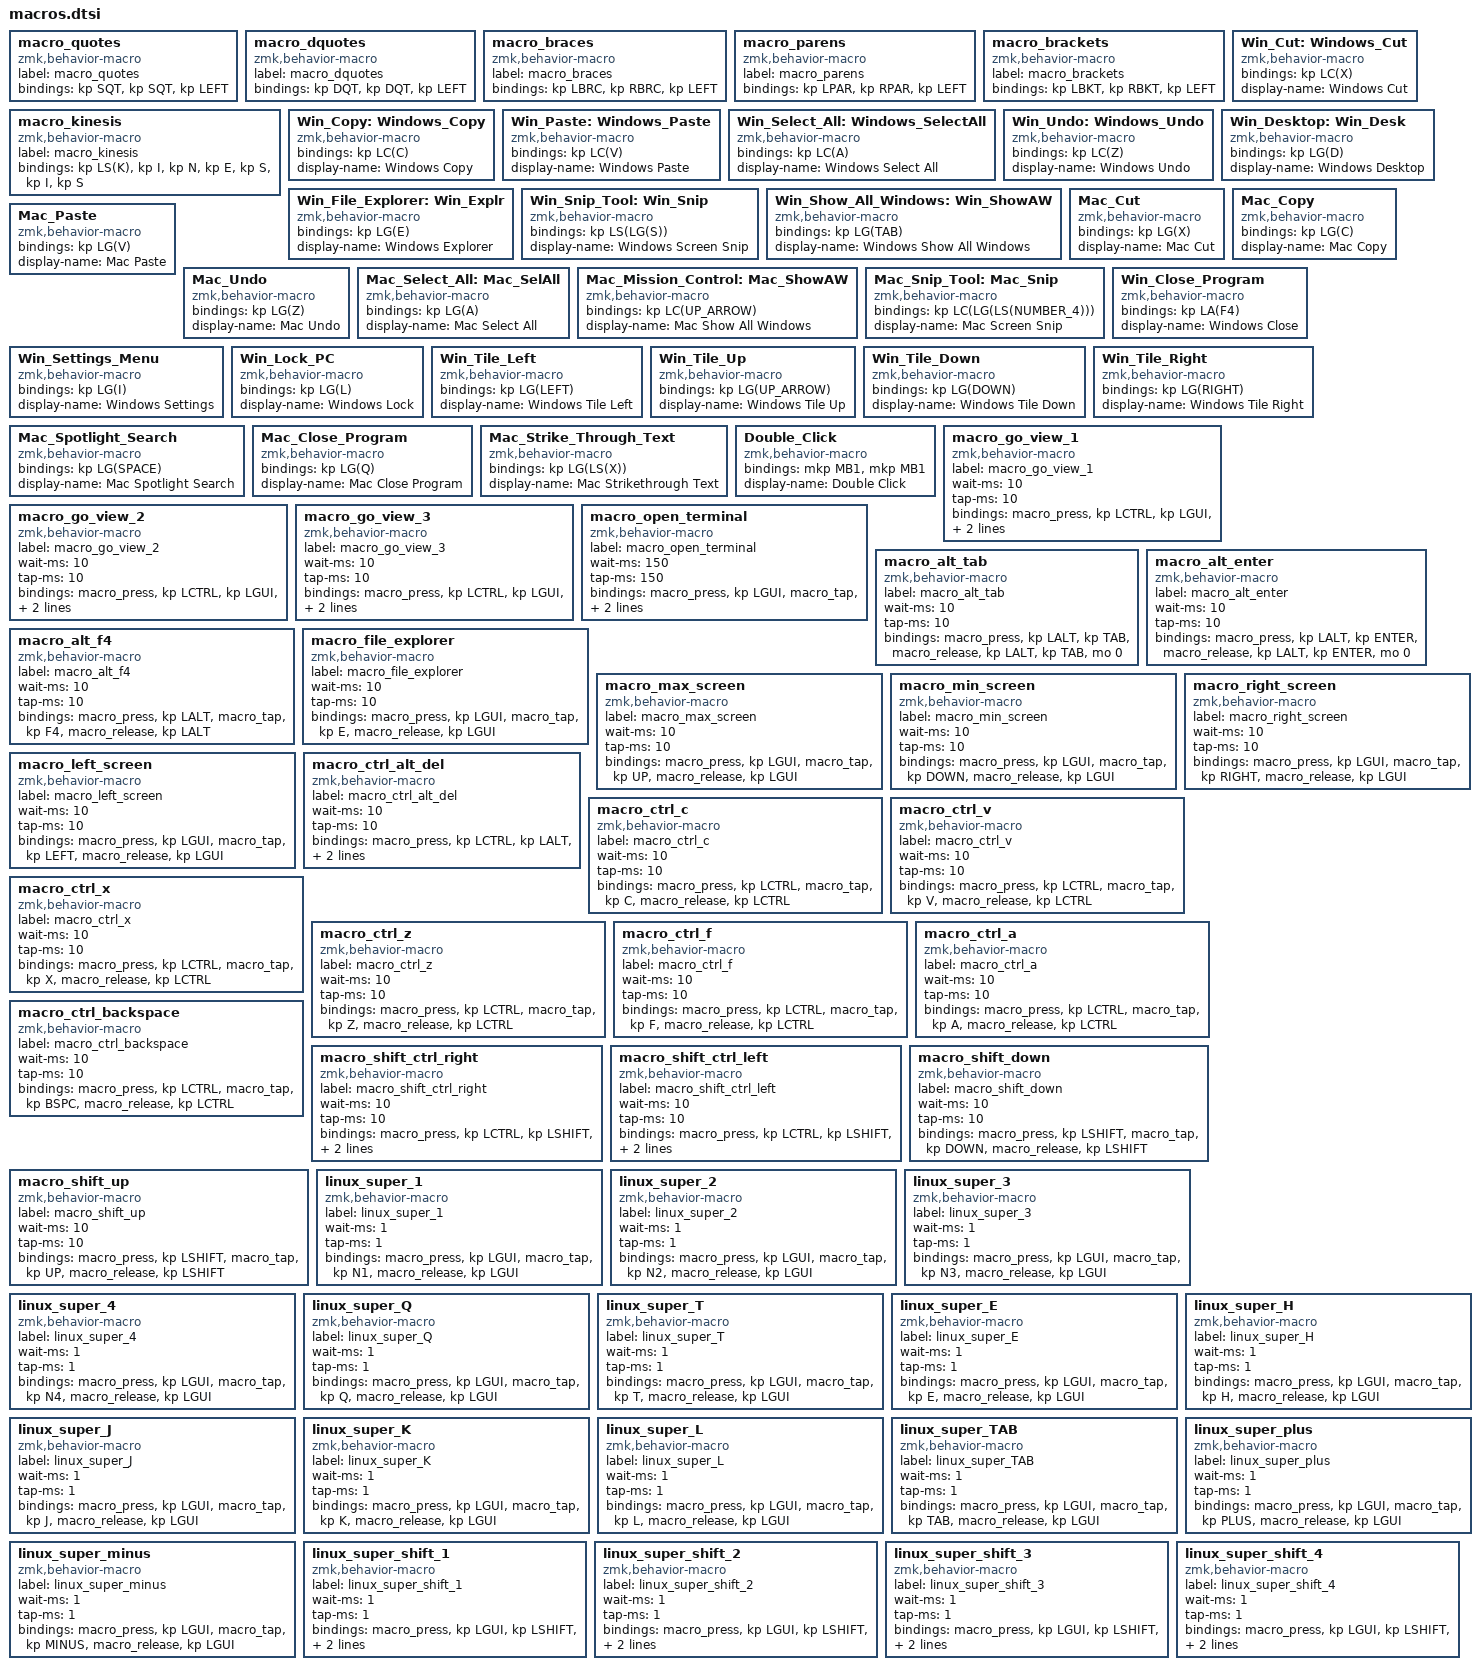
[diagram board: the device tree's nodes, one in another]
macro_quotes: macro_quotes {
    compatible = "zmk,behavior-macro";
    label = "macro_quotes";
    #binding-cells = <0>;
    bindings = <&kp SQT>, <&kp SQT>, <&kp LEFT>;
};
macro_dquotes: macro_dquotes {
    compatible = "zmk,behavior-macro";
    label = "macro_dquotes";
    #binding-cells = <0>;
    bindings = <&kp DQT>, <&kp DQT>, <&kp LEFT>;
};
macro_braces: macro_braces {
    compatible = "zmk,behavior-macro";
    label = "macro_braces";
    #binding-cells = <0>;
    bindings = <&kp LBRC>, <&kp RBRC>, <&kp LEFT>;
};
macro_parens: macro_parens {
    compatible = "zmk,behavior-macro";
    label = "macro_parens";
    #binding-cells = <0>;
    bindings = <&kp LPAR>, <&kp RPAR>, <&kp LEFT>;
};
macro_brackets: macro_brackets {
    compatible = "zmk,behavior-macro";
    label = "macro_brackets";
    #binding-cells = <0>;
    bindings = <&kp LBKT>, <&kp RBKT>, <&kp LEFT>;
};
macro_kinesis: macro_kinesis {
    compatible = "zmk,behavior-macro";
    label = "macro_kinesis";
    #binding-cells = <0>;
    bindings = <&kp LS(K)>, <&kp I>, <&kp N>, <&kp E>, <&kp S>, <&kp I>, <&kp S>;
};
Win_Cut: Windows_Cut {
    compatible = "zmk,behavior-macro";
    #binding-cells = <0>;
    bindings = <&kp LC(X)>;
    display-name = "Windows Cut";
};

Win_Copy: Windows_Copy {
    compatible = "zmk,behavior-macro";
    #binding-cells = <0>;
    bindings = <&kp LC(C)>;
    display-name = "Windows Copy";
};

Win_Paste: Windows_Paste {
    compatible = "zmk,behavior-macro";
    #binding-cells = <0>;
    bindings = <&kp LC(V)>;
    display-name = "Windows Paste";
};

Win_Select_All: Windows_SelectAll {
    compatible = "zmk,behavior-macro";
    #binding-cells = <0>;
    bindings = <&kp LC(A)>;
    display-name = "Windows Select All";
};

Win_Undo: Windows_Undo {
    compatible = "zmk,behavior-macro";
    #binding-cells = <0>;
    bindings = <&kp LC(Z)>;
    display-name = "Windows Undo";
};

Win_Desktop: Win_Desk {
    compatible = "zmk,behavior-macro";
    #binding-cells = <0>;
    bindings = <&kp LG(D)>;
    display-name = "Windows Desktop";
};

Win_File_Explorer: Win_Explr {
    compatible = "zmk,behavior-macro";
    #binding-cells = <0>;
    bindings = <&kp LG(E)>;
    display-name = "Windows Explorer";
};

Win_Snip_Tool: Win_Snip {
    compatible = "zmk,behavior-macro";
    #binding-cells = <0>;
    bindings = <&kp LS(LG(S))>;
    display-name = "Windows Screen Snip";
};

Win_Show_All_Windows: Win_ShowAW {
    compatible = "zmk,behavior-macro";
    #binding-cells = <0>;
    bindings = <&kp LG(TAB)>;
    display-name = "Windows Show All Windows";
};

Mac_Cut: Mac_Cut {
    compatible = "zmk,behavior-macro";
    #binding-cells = <0>;
    bindings = <&kp LG(X)>;
    display-name = "Mac Cut";
};

Mac_Copy: Mac_Copy {
    compatible = "zmk,behavior-macro";
    #binding-cells = <0>;
    bindings = <&kp LG(C)>;
    display-name = "Mac Copy";
};

Mac_Paste: Mac_Paste {
    compatible = "zmk,behavior-macro";
    #binding-cells = <0>;
    bindings = <&kp LG(V)>;
    display-name = "Mac Paste";
};

Mac_Undo: Mac_Undo {
    compatible = "zmk,behavior-macro";
    #binding-cells = <0>;
    bindings = <&kp LG(Z)>;
    display-name = "Mac Undo";
};

Mac_Select_All: Mac_SelAll {
    compatible = "zmk,behavior-macro";
    #binding-cells = <0>;
    bindings = <&kp LG(A)>;
    display-name = "Mac Select All";
};

Mac_Mission_Control: Mac_ShowAW {
    compatible = "zmk,behavior-macro";
    #binding-cells = <0>;
    bindings = <&kp LC(UP_ARROW)>;
    display-name = "Mac Show All Windows";
};

Mac_Snip_Tool: Mac_Snip {
    compatible = "zmk,behavior-macro";
    #binding-cells = <0>;
    bindings = <&kp LC(LG(LS(NUMBER_4)))>;
    display-name = "Mac Screen Snip";
};

Win_Close_Program: Win_Close_Program {
    compatible = "zmk,behavior-macro";
    #binding-cells = <0>;
    bindings = <&kp LA(F4)>;
    display-name = "Windows Close";
};

Win_Settings_Menu: Win_Settings_Menu {
    compatible = "zmk,behavior-macro";
    #binding-cells = <0>;
    bindings = <&kp LG(I)>;
    display-name = "Windows Settings";
};

Win_Lock_PC: Win_Lock_PC {
    compatible = "zmk,behavior-macro";
    #binding-cells = <0>;
    bindings = <&kp LG(L)>;
    display-name = "Windows Lock";
};

Win_Tile_Left: Win_Tile_Left {
    compatible = "zmk,behavior-macro";
    #binding-cells = <0>;
    bindings = <&kp LG(LEFT)>;
    display-name = "Windows Tile Left";
};

Win_Tile_Up: Win_Tile_Up {
    compatible = "zmk,behavior-macro";
    #binding-cells = <0>;
    bindings = <&kp LG(UP_ARROW)>;
    display-name = "Windows Tile Up";
};

Win_Tile_Down: Win_Tile_Down {
    compatible = "zmk,behavior-macro";
    #binding-cells = <0>;
    bindings = <&kp LG(DOWN)>;
    display-name = "Windows Tile Down";
};

Win_Tile_Right: Win_Tile_Right {
    compatible = "zmk,behavior-macro";
    #binding-cells = <0>;
    bindings = <&kp LG(RIGHT)>;
    display-name = "Windows Tile Right";
};

Mac_Spotlight_Search: Mac_Spotlight_Search {
    compatible = "zmk,behavior-macro";
    #binding-cells = <0>;
    bindings = <&kp LG(SPACE)>;
    display-name = "Mac Spotlight Search";
};

Mac_Close_Program: Mac_Close_Program {
    compatible = "zmk,behavior-macro";
    #binding-cells = <0>;
    bindings = <&kp LG(Q)>;
    display-name = "Mac Close Program";
};

Mac_Strike_Through_Text: Mac_Strike_Through_Text {
    compatible = "zmk,behavior-macro";
    #binding-cells = <0>;
    bindings = <&kp LG(LS(X))>;
    display-name = "Mac Strikethrough Text";
};

Double_Click: Double_Click {
    compatible = "zmk,behavior-macro";
    #binding-cells = <0>;
    bindings = <&mkp MB1 &mkp MB1>;
    display-name = "Double Click";
};

macro_go_view_1: macro_go_view_1 {
    label = "macro_go_view_1";
    compatible = "zmk,behavior-macro";
    #binding-cells = <0>;
    wait-ms = <10>;
    tap-ms = <10>;
    bindings 
    = <&macro_press &kp LCTRL &kp LGUI>
    , <&macro_tap &kp LEFT &kp LEFT>
    , <&macro_release &kp LCTRL &kp LGUI>;
};
macro_go_view_2: macro_go_view_2 {
    label = "macro_go_view_2";
    compatible = "zmk,behavior-macro";
    #binding-cells = <0>;
    wait-ms = <10>;
    tap-ms = <10>;
    bindings 
    = <&macro_press &kp LCTRL &kp LGUI>
    , <&macro_tap &kp LEFT &kp LEFT &kp RIGHT>
    , <&macro_release &kp LCTRL &kp LGUI>;
};
macro_go_view_3: macro_go_view_3 {
    label = "macro_go_view_3";
    compatible = "zmk,behavior-macro";
    #binding-cells = <0>;
    wait-ms = <10>;
    tap-ms = <10>;
    bindings 
    = <&macro_press &kp LCTRL &kp LGUI>
    , <&macro_tap &kp LEFT &kp LEFT &kp RIGHT &kp RIGHT>
    , <&macro_release &kp LCTRL &kp LGUI>;
};
macro_open_terminal: macro_open_terminal {
    label = "macro_open_terminal";
    compatible = "zmk,behavior-macro";
    #binding-cells = <0>;
    wait-ms = <150>;
    tap-ms = <150>;
    bindings 
    = <&macro_press &kp LGUI>
    , <&macro_tap &kp X>
    , <&macro_release &kp LGUI>
    , <&macro_tap &kp I>;
};
macro_alt_tab: macro_alt_tab {
    label = "macro_alt_tab";
    compatible = "zmk,behavior-macro";
    #binding-cells = <0>;
    wait-ms = <10>;
    tap-ms = <10>;
    bindings 
    = <&macro_press &kp LALT &kp TAB>
    , <&macro_release &kp LALT &kp TAB &mo 0>;
};
macro_alt_enter: macro_alt_enter {
    label = "macro_alt_enter";
    compatible = "zmk,behavior-macro";
    #binding-cells = <0>;
    wait-ms = <10>;
    tap-ms = <10>;
    bindings 
    = <&macro_press &kp LALT &kp ENTER>
    , <&macro_release &kp LALT &kp ENTER &mo 0>;
};
macro_alt_f4: macro_alt_f4 {
    label = "macro_alt_f4";
    compatible = "zmk,behavior-macro";
    #binding-cells = <0>;
    wait-ms = <10>;
    tap-ms = <10>;
    bindings 
    = <&macro_press &kp LALT>
    , <&macro_tap &kp F4>
    , <&macro_release &kp LALT>;
};
macro_file_explorer: macro_file_explorer {
    label = "macro_file_explorer";
    compatible = "zmk,behavior-macro";
    #binding-cells = <0>;
    wait-ms = <10>;
    tap-ms = <10>;
    bindings 
    = <&macro_press &kp LGUI>
    , <&macro_tap &kp E>
    , <&macro_release &kp LGUI>;
};
macro_max_screen: macro_max_screen {
    label = "macro_max_screen";
    compatible = "zmk,behavior-macro";
    #binding-cells = <0>;
    wait-ms = <10>;
    tap-ms = <10>;
    bindings 
    = <&macro_press &kp LGUI>
    , <&macro_tap &kp UP>
    , <&macro_release &kp LGUI>;
};
macro_min_screen: macro_min_screen {
    label = "macro_min_screen";
    compatible = "zmk,behavior-macro";
    #binding-cells = <0>;
    wait-ms = <10>;
    tap-ms = <10>;
    bindings 
    = <&macro_press &kp LGUI>
    , <&macro_tap &kp DOWN>
    , <&macro_release &kp LGUI>;
};
macro_right_screen: macro_right_screen {
    label = "macro_right_screen";
    compatible = "zmk,behavior-macro";
    #binding-cells = <0>;
    wait-ms = <10>;
    tap-ms = <10>;
    bindings 
    = <&macro_press &kp LGUI>
    , <&macro_tap &kp RIGHT>
    , <&macro_release &kp LGUI>;
};
macro_left_screen: macro_left_screen {
    label = "macro_left_screen";
    compatible = "zmk,behavior-macro";
    #binding-cells = <0>;
    wait-ms = <10>;
    tap-ms = <10>;
    bindings 
    = <&macro_press &kp LGUI>
    , <&macro_tap &kp LEFT>
    , <&macro_release &kp LGUI>;
};
macro_ctrl_alt_del: macro_ctrl_alt_del {
    label = "macro_ctrl_alt_del";
    compatible = "zmk,behavior-macro";
    #binding-cells = <0>;
    wait-ms = <10>;
    tap-ms = <10>;
    bindings 
    = <&macro_press &kp LCTRL &kp LALT>
    , <&macro_tap &kp DEL>
    , <&macro_release &kp LCTRL &kp LALT>;
};
macro_ctrl_c: macro_ctrl_c {
    label = "macro_ctrl_c";
    compatible = "zmk,behavior-macro";
    #binding-cells = <0>;
    wait-ms = <10>;
    tap-ms = <10>;
    bindings 
    = <&macro_press &kp LCTRL>
    , <&macro_tap &kp C>
    , <&macro_release &kp LCTRL>;
};
macro_ctrl_v: macro_ctrl_v {
    label = "macro_ctrl_v";
    compatible = "zmk,behavior-macro";
    #binding-cells = <0>;
    wait-ms = <10>;
    tap-ms = <10>;
    bindings 
    = <&macro_press &kp LCTRL>
    , <&macro_tap &kp V>
    , <&macro_release &kp LCTRL>;
};
macro_ctrl_x: macro_ctrl_x {
    label = "macro_ctrl_x";
    compatible = "zmk,behavior-macro";
    #binding-cells = <0>;
    wait-ms = <10>;
    tap-ms = <10>;
    bindings 
    = <&macro_press &kp LCTRL>
    , <&macro_tap &kp X>
    , <&macro_release &kp LCTRL>;
};
macro_ctrl_z: macro_ctrl_z {
    label = "macro_ctrl_z";
    compatible = "zmk,behavior-macro";
    #binding-cells = <0>;
    wait-ms = <10>;
    tap-ms = <10>;
    bindings 
    = <&macro_press &kp LCTRL>
    , <&macro_tap &kp Z>
    , <&macro_release &kp LCTRL>;
};
macro_ctrl_f: macro_ctrl_f {
    label = "macro_ctrl_f";
    compatible = "zmk,behavior-macro";
    #binding-cells = <0>;
    wait-ms = <10>;
    tap-ms = <10>;
    bindings 
    = <&macro_press &kp LCTRL>
    , <&macro_tap &kp F>
    , <&macro_release &kp LCTRL>;
};
macro_ctrl_a: macro_ctrl_a {
    label = "macro_ctrl_a";
    compatible = "zmk,behavior-macro";
    #binding-cells = <0>;
    wait-ms = <10>;
    tap-ms = <10>;
    bindings 
    = <&macro_press &kp LCTRL>
    , <&macro_tap &kp A>
    , <&macro_release &kp LCTRL>;
};
macro_ctrl_backspace: macro_ctrl_backspace {
    label = "macro_ctrl_backspace";
    compatible = "zmk,behavior-macro";
    #binding-cells = <0>;
    wait-ms = <10>;
    tap-ms = <10>;
    bindings 
    = <&macro_press &kp LCTRL>
    , <&macro_tap &kp BSPC>
    , <&macro_release &kp LCTRL>;
};
macro_shift_ctrl_right: macro_shift_ctrl_right {
    label = "macro_shift_ctrl_right";
    compatible = "zmk,behavior-macro";
    #binding-cells = <0>;
    wait-ms = <10>;
    tap-ms = <10>;
    bindings 
    = <&macro_press &kp LCTRL &kp LSHIFT>
    , <&macro_tap &kp RIGHT>
    , <&macro_release &kp LCTRL &kp LSHIFT>;
};
macro_shift_ctrl_left: macro_shift_ctrl_left {
    label = "macro_shift_ctrl_left";
    compatible = "zmk,behavior-macro";
    #binding-cells = <0>;
    wait-ms = <10>;
    tap-ms = <10>;
    bindings 
    = <&macro_press &kp LCTRL &kp LSHIFT>
    , <&macro_tap &kp LEFT>
    , <&macro_release &kp LCTRL &kp LSHIFT>;
};
macro_shift_down: macro_shift_down {
    label = "macro_shift_down";
    compatible = "zmk,behavior-macro";
    #binding-cells = <0>;
    wait-ms = <10>;
    tap-ms = <10>;
    bindings 
    = <&macro_press &kp LSHIFT>
    , <&macro_tap &kp DOWN>
    , <&macro_release &kp LSHIFT>;
};
macro_shift_up: macro_shift_up {
    label = "macro_shift_up";
    compatible = "zmk,behavior-macro";
    #binding-cells = <0>;
    wait-ms = <10>;
    tap-ms = <10>;
    bindings 
    = <&macro_press &kp LSHIFT>
    , <&macro_tap &kp UP>
    , <&macro_release &kp LSHIFT>;
};

linux_super_1: linux_super_1 {
    label = "linux_super_1";
    compatible = "zmk,behavior-macro";
    #binding-cells = <0>;
    wait-ms = <1>;
    tap-ms = <1>;
    bindings 
    = <&macro_press &kp LGUI>
    , <&macro_tap &kp N1>
    , <&macro_release &kp LGUI>;
};


linux_super_2: linux_super_2 {
    label = "linux_super_2";
    compatible = "zmk,behavior-macro";
    #binding-cells = <0>;
    wait-ms = <1>;
    tap-ms = <1>;
    bindings 
    = <&macro_press &kp LGUI>
    , <&macro_tap &kp N2>
    , <&macro_release &kp LGUI>;
};

linux_super_3: linux_super_3 {
    label = "linux_super_3";
    compatible = "zmk,behavior-macro";
    #binding-cells = <0>;
    wait-ms = <1>;
    tap-ms = <1>;
    bindings 
    = <&macro_press &kp LGUI>
    , <&macro_tap &kp N3>
    , <&macro_release &kp LGUI>;
};


linux_super_4: linux_super_4 {
    label = "linux_super_4";
    compatible = "zmk,behavior-macro";
    #binding-cells = <0>;
    wait-ms = <1>;
    tap-ms = <1>;
    bindings 
    = <&macro_press &kp LGUI>
    , <&macro_tap &kp N4>
    , <&macro_release &kp LGUI>;
};


linux_super_Q: linux_super_Q {
    label = "linux_super_Q";
    compatible = "zmk,behavior-macro";
    #binding-cells = <0>;
    wait-ms = <1>;
    tap-ms = <1>;
    bindings 
    = <&macro_press &kp LGUI>
    , <&macro_tap &kp Q>
    , <&macro_release &kp LGUI>;
};


linux_super_T: linux_super_T {
    label = "linux_super_T";
    compatible = "zmk,behavior-macro";
    #binding-cells = <0>;
    wait-ms = <1>;
    tap-ms = <1>;
    bindings 
    = <&macro_press &kp LGUI>
    , <&macro_tap &kp T>
    , <&macro_release &kp LGUI>;
};

linux_super_E: linux_super_E {
    label = "linux_super_E";
    compatible = "zmk,behavior-macro";
    #binding-cells = <0>;
    wait-ms = <1>;
    tap-ms = <1>;
    bindings 
    = <&macro_press &kp LGUI>
    , <&macro_tap &kp E>
    , <&macro_release &kp LGUI>;
};

linux_super_H: linux_super_H {
    label = "linux_super_H";
    compatible = "zmk,behavior-macro";
    #binding-cells = <0>;
    wait-ms = <1>;
    tap-ms = <1>;
    bindings 
    = <&macro_press &kp LGUI>
    , <&macro_tap &kp H>
    , <&macro_release &kp LGUI>;
};

linux_super_J: linux_super_J {
    label = "linux_super_J";
    compatible = "zmk,behavior-macro";
    #binding-cells = <0>;
    wait-ms = <1>;
    tap-ms = <1>;
    bindings 
    = <&macro_press &kp LGUI>
    , <&macro_tap &kp J>
    , <&macro_release &kp LGUI>;
};

linux_super_K: linux_super_K {
    label = "linux_super_K";
    compatible = "zmk,behavior-macro";
    #binding-cells = <0>;
    wait-ms = <1>;
    tap-ms = <1>;
    bindings 
    = <&macro_press &kp LGUI>
    , <&macro_tap &kp K>
    , <&macro_release &kp LGUI>;
};

linux_super_L: linux_super_L {
    label = "linux_super_L";
    compatible = "zmk,behavior-macro";
    #binding-cells = <0>;
    wait-ms = <1>;
    tap-ms = <1>;
    bindings 
    = <&macro_press &kp LGUI>
    , <&macro_tap &kp L>
    , <&macro_release &kp LGUI>;
};

linux_super_TAB: linux_super_TAB {
    label = "linux_super_TAB";
    compatible = "zmk,behavior-macro";
    #binding-cells = <0>;
    wait-ms = <1>;
    tap-ms = <1>;
    bindings 
    = <&macro_press &kp LGUI>
    , <&macro_tap &kp TAB>
    , <&macro_release &kp LGUI>;
};

linux_super_plus: linux_super_plus {
    label = "linux_super_plus";
    compatible = "zmk,behavior-macro";
    #binding-cells = <0>;
    wait-ms = <1>;
    tap-ms = <1>;
    bindings 
    = <&macro_press &kp LGUI>
    , <&macro_tap &kp PLUS>
    , <&macro_release &kp LGUI>;
};

linux_super_minus: linux_super_minus {
    label = "linux_super_minus";
    compatible = "zmk,behavior-macro";
    #binding-cells = <0>;
    wait-ms = <1>;
    tap-ms = <1>;
    bindings 
    = <&macro_press &kp LGUI>
    , <&macro_tap &kp MINUS>
    , <&macro_release &kp LGUI>;
};

linux_super_shift_1: linux_super_shift_1 {
    label = "linux_super_shift_1";
    compatible = "zmk,behavior-macro";
    #binding-cells = <0>;
    wait-ms = <1>;
    tap-ms = <1>;
    bindings 
    = <&macro_press &kp LGUI &kp LSHIFT>
    , <&macro_tap &kp N1>
    , <&macro_release &kp LGUI &kp LSHIFT>;
};

linux_super_shift_2: linux_super_shift_2 {
    label = "linux_super_shift_2";
    compatible = "zmk,behavior-macro";
    #binding-cells = <0>;
    wait-ms = <1>;
    tap-ms = <1>;
    bindings 
    = <&macro_press &kp LGUI &kp LSHIFT>
    , <&macro_tap &kp N2>
    , <&macro_release &kp LGUI &kp LSHIFT>;
};


linux_super_shift_3: linux_super_shift_3 {
    label = "linux_super_shift_3";
    compatible = "zmk,behavior-macro";
    #binding-cells = <0>;
    wait-ms = <1>;
    tap-ms = <1>;
    bindings 
    = <&macro_press &kp LGUI &kp LSHIFT>
    , <&macro_tap &kp N3>
    , <&macro_release &kp LGUI &kp LSHIFT>;
};

linux_super_shift_4: linux_super_shift_4 {
    label = "linux_super_shift_4";
    compatible = "zmk,behavior-macro";
    #binding-cells = <0>;
    wait-ms = <1>;
    tap-ms = <1>;
    bindings 
    = <&macro_press &kp LGUI &kp LSHIFT>
    , <&macro_tap &kp N4>
    , <&macro_release &kp LGUI &kp LSHIFT>;
};
